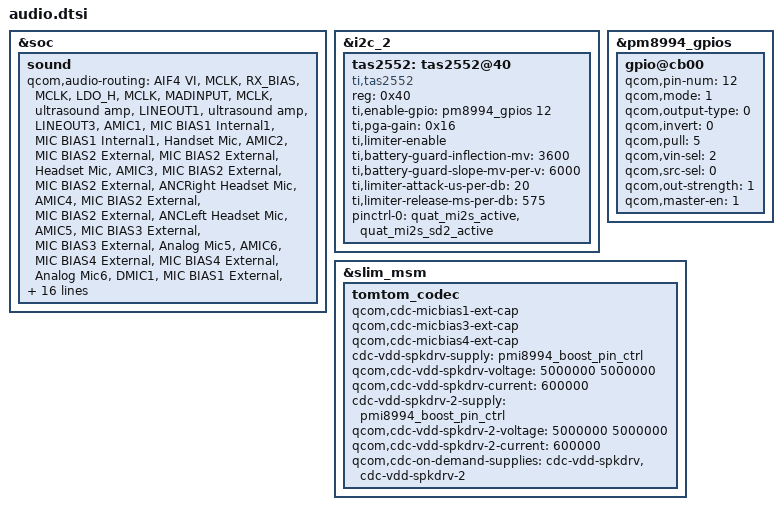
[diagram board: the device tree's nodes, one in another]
/* Copyright (c) 2014-2015, The Linux Foundation. All rights reserved.
 *
 * This program is free software; you can redistribute it and/or modify
 * it under the terms of the GNU General Public License version 2 and
 * only version 2 as published by the Free Software Foundation.
 *
 * This program is distributed in the hope that it will be useful,
 * but WITHOUT ANY WARRANTY; without even the implied warranty of
 * MERCHANTABILITY or FITNESS FOR A PARTICULAR PURPOSE.  See the
 * GNU General Public License for more details.
 */
 
&soc {
	sound {
		qcom,audio-routing =
			"AIF4 VI", "MCLK",
			"RX_BIAS", "MCLK",
			"LDO_H", "MCLK",
			"MADINPUT", "MCLK",
			"ultrasound amp", "LINEOUT1",
			"ultrasound amp", "LINEOUT3",
			"AMIC1", "MIC BIAS1 Internal1",
			"MIC BIAS1 Internal1", "Handset Mic",
			"AMIC2", "MIC BIAS2 External",
			"MIC BIAS2 External", "Headset Mic",
			"AMIC3", "MIC BIAS2 External",
			"MIC BIAS2 External", "ANCRight Headset Mic",
			"AMIC4", "MIC BIAS2 External",
			"MIC BIAS2 External", "ANCLeft Headset Mic",
			"AMIC5", "MIC BIAS3 External",
			"MIC BIAS3 External", "Analog Mic5",
			"AMIC6", "MIC BIAS4 External",
			"MIC BIAS4 External", "Analog Mic6",
			"DMIC1", "MIC BIAS1 External",
			"MIC BIAS1 External", "Digital Mic1",
			"DMIC2", "MIC BIAS1 External",
			"MIC BIAS1 External", "Digital Mic2",
			"DMIC3", "MIC BIAS3 External",
			"MIC BIAS3 External", "Digital Mic3",
			"DMIC4", "MIC BIAS3 External",
			"MIC BIAS3 External", "Digital Mic4",
			"DMIC5", "MIC BIAS4 External",
			"MIC BIAS4 External", "Digital Mic5",
			"DMIC6", "MIC BIAS4 External",
			"MIC BIAS4 External", "Digital Mic6";

		qcom,us-euro-gpios = <&pm8994_mpps 2 0>;
		qcom,cdc-micbias2-headset-only;
		qcom,mbhc-audio-jack-type = "4-pole-jack";
		qcom,mbhc-insert-detect-inverted;
		qcom,ext-ult-spk-amp-gpio = <&pmi8994_gpios 1 0>;
		asoc-codec = <&stub_codec>;
		asoc-codec-names = "msm-stub-codec.1";
	};
};

/*
 * The main loudspeaker hangs off a TI TAS2553 (register compatible with the
 * TAS2552) rather than the WCD9330's own speaker driver. It is controlled
 * over BLSP1 I2C-2 and fed audio over Quaternary MI2S.
 *
 * The MI2S pins are claimed here as the amplifier's "default" pinctrl state
 * instead of being switched by the sound card: the ASoC machine driver
 * already owns a pinctrl handle for the sound node, and pinctrl_get() hands
 * back that same handle, so a second consumer selecting states on it would
 * silently tear down the primary MI2S and AuxPCM pin configuration. Nothing
 * else on the board can use GPIO 58/59/62, so a static mux is correct.
 */
&i2c_2 {
	status = "ok";

	tas2552: tas2552@40 {
		compatible = "ti,tas2552";
		reg = <0x40>;

		ti,enable-gpio = <&pm8994_gpios 12 0>;

		/*
		 * PGA 0x16 = 15 dB, the chip default (SLAS978B 7.5.20,
		 * PGA_GAIN = N - 7 dB). 15 dB with the Battery Tracking AGC
		 * off power-cycled the PMIC mid-playback on an old BV-T5E
		 * pack; 0x12 (11 dB) was the stable fallback. What makes
		 * 15 dB acceptable again is the guard below, not a healthier
		 * battery: drop back to <0x12> if the phone still resets.
		 */
		ti,pga-gain = <0x16>;

		/*
		 * Battery Tracking AGC (SLAS978B 7.3.10, 7.5.13-7.5.17).
		 * LIM_EN, CONFIG2 bit 2. Above the inflection point the peak
		 * output is limited by the boost rail; below it VLIM falls by
		 * the slope for every volt VBAT drops, which is what cuts the
		 * 2.5 A boost peaks (9.3) before the PMIC undervoltage trips.
		 *
		 * inflection 3600 mV -> 0x0B = 0x90. The TI characterisation
		 *   in the datasheet uses 3.6 V, and the BV-T5E's loaded
		 *   voltage on a near-empty or aged pack sits around there.
		 * slope 6000 mV/V -> 0x0C = 0x81, the chip default region
		 *   (0x80 = 5.97 V/V): at VBAT 3.3 V the peak drops by ~1.8 V,
		 *   at 3.0 V by ~3.6 V.
		 * attack 20 us/dB -> 0x0E[2:0] = 0, fastest, so a transient
		 *   is caught within the boost's own response time.
		 * release 575 ms/dB -> 0x0F[3:0] = 5, the register default,
		 *   slow enough not to pump.
		 * Register 0x0D takes the TAS2553 init value 0xA9 (8.3).
		 */
		ti,limiter-enable;
		ti,battery-guard-inflection-mv = <3600>;
		ti,battery-guard-slope-mv-per-v = <6000>;
		ti,limiter-attack-us-per-db = <20>;
		ti,limiter-release-ms-per-db = <575>;

		pinctrl-names = "default";
		pinctrl-0 = <&quat_mi2s_active>, <&quat_mi2s_sd2_active>;
	};
};

/*
 * Amplifier enable. The schematic labels TLMM GPIO 144 as the speaker enable,
 * but on production hardware the line that actually gates the TAS2553 is
 * PM8994 GPIO 12 -- with it low the chip does not acknowledge on I2C at all.
 */
&pm8994_gpios {
	gpio@cb00 {
		status = "ok";
		qcom,pin-num = <12>;
		qcom,mode = <1>;		/* digital output */
		qcom,output-type = <0>;		/* CMOS */
		qcom,invert = <0>;		/* start low, amp off */
		qcom,pull = <5>;		/* no pull */
		qcom,vin-sel = <2>;		/* 1.8 V */
		qcom,src-sel = <0>;		/* constant */
		qcom,out-strength = <1>;	/* low */
		qcom,master-en = <1>;
	};
};

&slim_msm {
	tomtom_codec {
		qcom,cdc-micbias1-ext-cap;
		qcom,cdc-micbias3-ext-cap;
		qcom,cdc-micbias4-ext-cap;
		cdc-vdd-spkdrv-supply = <&pmi8994_boost_pin_ctrl>;
		qcom,cdc-vdd-spkdrv-voltage = <5000000 5000000>;
		qcom,cdc-vdd-spkdrv-current = <600000>;

		cdc-vdd-spkdrv-2-supply = <&pmi8994_boost_pin_ctrl>;
		qcom,cdc-vdd-spkdrv-2-voltage = <5000000 5000000>;
		qcom,cdc-vdd-spkdrv-2-current = <600000>;

		qcom,cdc-on-demand-supplies = "cdc-vdd-spkdrv",
					      "cdc-vdd-spkdrv-2";
	};
};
